# STM32G07x register map
File version: 1.3
CPU: CM0+ r0p0, little endian, no MPU, no FPU, 3 interrupt priority bits
Registers are 32-bit, read-write, reset 0x0 unless marked. A register's access mark holds for its fields unless they carry their own. Offsets are from the block's base; [hi:lo] are bit positions; {n}, {i} and the like mark numbered series; 'fields as' and 'values as' point back to an identical list.

## DMA — DMA controller
Base 0x40020000
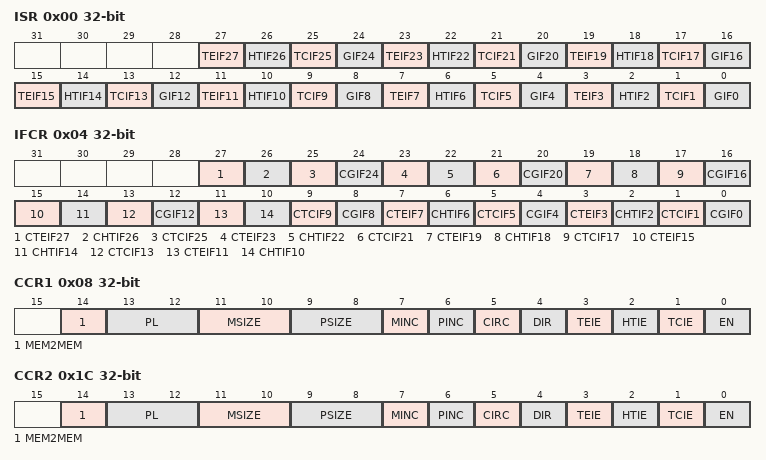
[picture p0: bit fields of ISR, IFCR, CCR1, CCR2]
0x00 ISR ro — low interrupt status register
  [27] TEIF27 — Channel transfer error flag
  [26] HTIF26 — Channel half transfer flag
  [25] TCIF25 — Channel transfer complete flag
  [24] GIF24 — Channel global interrupt flag
  [23] TEIF23 — Channel transfer error flag
  [22] HTIF22 — Channel half transfer flag
  [21] TCIF21 — Channel transfer complete flag
  [20] GIF20 — Channel global interrupt flag
  [19] TEIF19 — Channel transfer error flag
  [18] HTIF18 — Channel half transfer flag
  [17] TCIF17 — Channel transfer complete flag
  [16] GIF16 — Channel global interrupt flag
  [15] TEIF15 — Channel transfer error flag
  [14] HTIF14 — Channel half transfer flag
  [13] TCIF13 — Channel transfer complete flag
  [12] GIF12 — Channel global interrupt flag
  [11] TEIF11 — Channel transfer error flag
  [10] HTIF10 — Channel half transfer flag
  [9] TCIF9 — Channel transfer complete flag
  [8] GIF8 — Channel global interrupt flag
  [7] TEIF7 — Channel transfer error flag
  [6] HTIF6 — Channel half transfer flag
  [5] TCIF5 — Channel transfer complete flag
  [4] GIF4 — Channel global interrupt flag
  [3] TEIF3 — Channel transfer error flag
  [2] HTIF2 — Channel half transfer flag
  [1] TCIF1 — Channel transfer complete flag
  [0] GIF0 — Channel global interrupt flag
0x04 IFCR ro — high interrupt status register
  [27] CTEIF27 — Channel transfer error flag
  [26] CHTIF26 — Channel half transfer flag
  [25] CTCIF25 — Channel transfer complete flag
  [24] CGIF24 — Channel global interrupt flag
  [23] CTEIF23 — Channel transfer error flag
  [22] CHTIF22 — Channel half transfer flag
  [21] CTCIF21 — Channel transfer complete flag
  [20] CGIF20 — Channel global interrupt flag
  [19] CTEIF19 — Channel transfer error flag
  [18] CHTIF18 — Channel half transfer flag
  [17] CTCIF17 — Channel transfer complete flag
  [16] CGIF16 — Channel global interrupt flag
  [15] CTEIF15 — Channel transfer error flag
  [14] CHTIF14 — Channel half transfer flag
  [13] CTCIF13 — Channel transfer complete flag
  [12] CGIF12 — Channel global interrupt flag
  [11] CTEIF11 — Channel transfer error flag
  [10] CHTIF10 — Channel half transfer flag
  [9] CTCIF9 — Channel transfer complete flag
  [8] CGIF8 — Channel global interrupt flag
  [7] CTEIF7 — Channel transfer error flag
  [6] CHTIF6 — Channel half transfer flag
  [5] CTCIF5 — Channel transfer complete flag
  [4] CGIF4 — Channel global interrupt flag
  [3] CTEIF3 — Channel transfer error flag
  [2] CHTIF2 — Channel half transfer flag
  [1] CTCIF1 — Channel transfer complete flag
  [0] CGIF0 — Channel global interrupt flag
0x08 CCR1 — DMA channel x configuration register
  [14] MEM2MEM — Memory to memory mode
  [13:12] PL — Channel priority level
  [11:10] MSIZE — Memory size
  [9:8] PSIZE — Peripheral size
  [7] MINC — Memory increment mode
  [6] PINC — Peripheral increment mode
  [5] CIRC — Circular mode
  [4] DIR — Data transfer direction
  [3] TEIE — Transfer error interrupt enable
  [2] HTIE — Half transfer interrupt enable
  [1] TCIE — Transfer complete interrupt enable
  [0] EN — Channel enable
0x0C CNDTR1 — DMA channel x number of data register
  [15:0] NDT — Number of data to transfer
0x10 CPAR1 — DMA channel x peripheral address register
  [31:0] PA — Peripheral address
{0x0+0x14*i} CMAR{i} (i=1..7) — DMA channel x memory address register
  [31:0] MA — Memory address
0x1C CCR2 — DMA channel x configuration register
  fields as CCR1
0x20 CNDTR2 — DMA channel x number of data register
  [15:0] NDT — Number of data to transfer
0x24 CPAR2 — DMA channel x peripheral address register
  [31:0] PA — Peripheral address
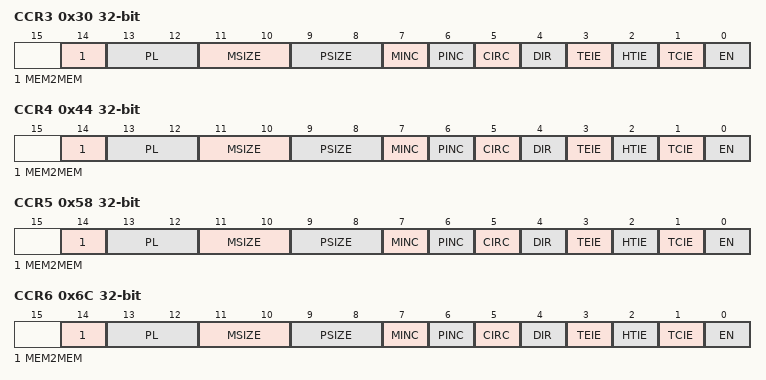
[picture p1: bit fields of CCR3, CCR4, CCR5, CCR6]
0x30 CCR3 — DMA channel x configuration register
  fields as CCR1
0x34 CNDTR3 — DMA channel x configuration register
  [15:0] NDT — Number of data to transfer
0x38 CPAR3 — DMA channel x peripheral address register
  [31:0] PA — Peripheral address
0x44 CCR4 — DMA channel x configuration register
  fields as CCR1
0x48 CNDTR4 — DMA channel x configuration register
  [15:0] NDT — Number of data to transfer
0x4C CPAR4 — DMA channel x peripheral address register
  [31:0] PA — Peripheral address
0x58 CCR5 — DMA channel x configuration register
  fields as CCR1
0x5C CNDTR5 — DMA channel x configuration register
  [15:0] NDT — Number of data to transfer
0x60 CPAR5 — DMA channel x peripheral address register
  [31:0] PA — Peripheral address
0x6C CCR6 — DMA channel x configuration register
  fields as CCR1
0x70 CNDTR6 — DMA channel x configuration register
  [15:0] NDT — Number of data to transfer
0x74 CPAR6 — DMA channel x peripheral address register
  [31:0] PA — Peripheral address
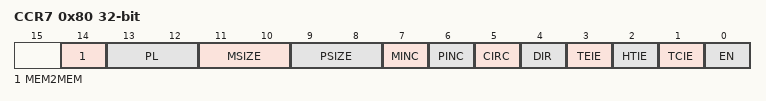
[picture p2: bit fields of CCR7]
0x80 CCR7 — DMA channel x configuration register
  fields as CCR1
0x84 CNDTR7 — DMA channel x configuration register
  [15:0] NDT — Number of data to transfer
0x88 CPAR7 — DMA channel x peripheral address register
  [31:0] PA — Peripheral address
